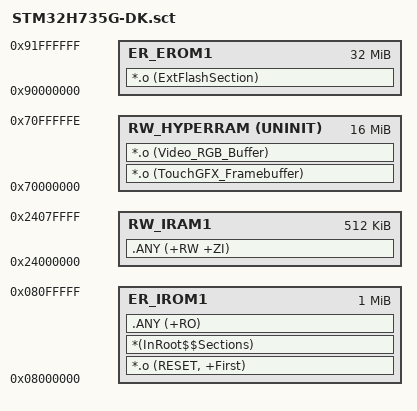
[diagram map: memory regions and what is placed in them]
; *************************************************************
; *** Scatter-Loading Description File generated by uVision ***
; *************************************************************

LR_IROM1 0x08000000 0x00100000  {    ; load region size_region
  ER_IROM1 0x08000000 0x00100000  {  ; load address = execution address
   *.o (RESET, +First)
   *(InRoot$$Sections)
   .ANY (+RO)
  }
  RW_IRAM1 0x24000000 0x00080000  {  ; RW data
   .ANY (+RW +ZI)
  }
  RW_HYPERRAM 0x70000000 UNINIT 0x00FFFFFF {
	*.o (TouchGFX_Framebuffer)
	*.o (Video_RGB_Buffer)
  }
}

LR_EROM1 0x90000000 0x2000000  {    ; load region size_region
  ER_EROM1 0x90000000 0x2000000  {  ; load address = execution address
   *.o (ExtFlashSection)
;  *.o (TextFlashSection)
;  *.o (FontFlashSection)
  }
}

